# APM32F103x4 register map
File version: 1.0
CPU: CM3 r2p1, little endian, no MPU, no FPU, 4 interrupt priority bits
Registers are 32-bit, read-write, reset 0x0 unless marked. A register's access mark holds for its fields unless they carry their own. Offsets are from the block's base; [hi:lo] are bit positions; {n}, {i} and the like mark numbered series.

## GPIOA — General purpose I/O
Base 0x40010800
Same registers: GPIOB 0x40010C00, GPIOC 0x40011000, GPIOD 0x40011400
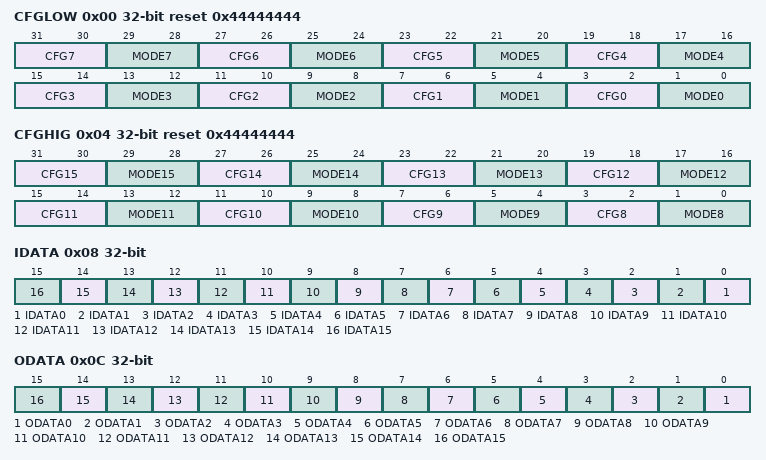
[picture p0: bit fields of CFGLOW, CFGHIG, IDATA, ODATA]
0x00 CFGLOW reset 0x44444444 — Port configuration register 0 (GPIOn_CFGLOW)
  [31:30] CFG7 — Port n.7 configuration bits
  [29:28] MODE7 — Port n.7 mode bits
  [27:26] CFG6 — Port n.6 configuration bits
  [25:24] MODE6 — Port n.6 mode bits
  [23:22] CFG5 — Port n.5 configuration bits
  [21:20] MODE5 — Port n.5 mode bits
  [19:18] CFG4 — Port n.4 configuration bits
  [17:16] MODE4 — Port n.4 mode bits
  [15:14] CFG3 — Port n.3 configuration bits
  [13:12] MODE3 — Port n.3 mode bits
  [11:10] CFG2 — Port n.2 configuration bits
  [9:8] MODE2 — Port n.2 mode bits
  [7:6] CFG1 — Port n.1 configuration bits
  [5:4] MODE1 — Port n.1 mode bits
  [3:2] CFG0 — Port n.0 configuration bits
  [1:0] MODE0 — Port n.0 mode bits
0x04 CFGHIG reset 0x44444444 — Port configuration register 1 (GPIOn_CFGHIG)
  [31:30] CFG15 — Port n.15 configuration bits
  [29:28] MODE15 — Port n.15 mode bits
  [27:26] CFG14 — Port n.14 configuration bits
  [25:24] MODE14 — Port n.14 mode bits
  [23:22] CFG13 — Port n.13 configuration bits
  [21:20] MODE13 — Port n.13 mode bits
  [19:18] CFG12 — Port n.12 configuration bits
  [17:16] MODE12 — Port n.12 mode bits
  [15:14] CFG11 — Port n.11 configuration bits
  [13:12] MODE11 — Port n.11 mode bits
  [11:10] CFG10 — Port n.10 configuration bits
  [9:8] MODE10 — Port n.10 mode bits
  [7:6] CFG9 — Port n.9 configuration bits
  [5:4] MODE9 — Port n.9 mode bits
  [3:2] CFG8 — Port n.8 configuration bits
  [1:0] MODE8 — Port n.8 mode bits
0x08 IDATA ro — Port input data register (GPIOn_IDATA)
  [n] IDATA{n} (n=0..15) — Port input data
0x0C ODATA — Port output data register (GPIOn_ODATA)
  [n] ODATA{n} (n=0..15) — Port output data
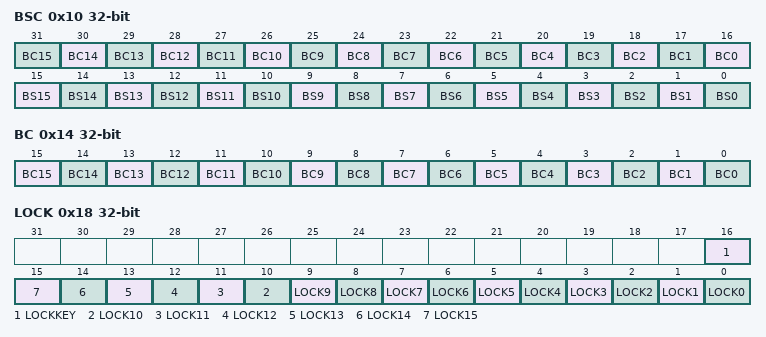
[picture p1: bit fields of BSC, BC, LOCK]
0x10 BSC wo — Port bit set/reset register (GPIOn_BSC)
  [n+16] BC{n} (n=0..15) — Clear bit {n}
  [n] BS{n} (n=3..15) — Set bit {n}
  [2] BS2 — Set bit 1
  [1] BS1 — Set bit 1
  [0] BS0 — Set bit 0
0x14 BC wo — Port bit clear register (GPIOn_BC)
  [n] BC{n} (n=3..15) — Clear bit {n}
  [2] BC2 — Clear bit 1
  [1] BC1 — Clear bit 1
  [0] BC0 — Clear bit 0
0x18 LOCK — Port configuration lock register (GPIOn_LOCK)
  [16] LOCKKEY
  [n] LOCK{n} (n=0..15) — Port A Lock bit {n}

## EINT — External Interrupt
Base 0x40010400
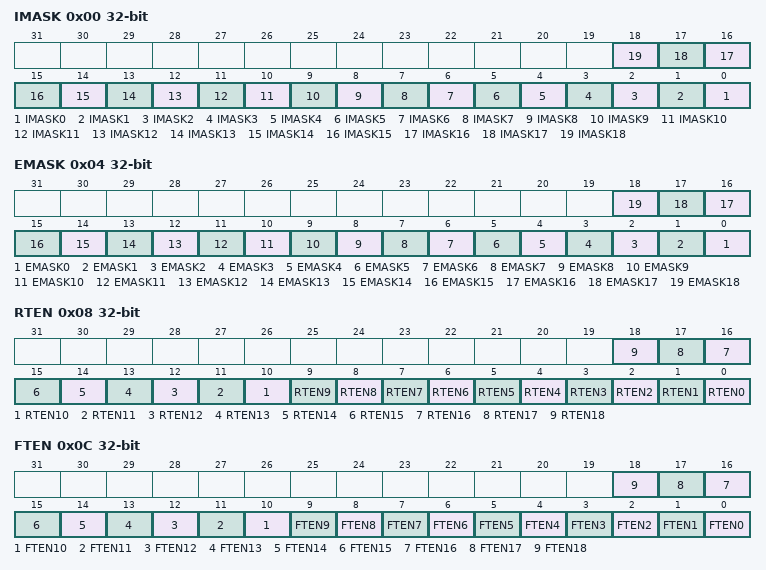
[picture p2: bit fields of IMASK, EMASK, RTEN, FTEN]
0x00 IMASK — Interrupt mask register (EINT_IMASK)
  [n] IMASK{n} (n=0..18) — Interrupt Mask on line {n}
0x04 EMASK — Event mask register (EINT_EMASK)
  [n] EMASK{n} (n=0..18) — Event Mask on line {n}
0x08 RTEN — Rising Trigger selection register (EINT_RTEN)
  [n] RTEN{n} (n=0..18) — Rising trigger event configuration of line {n}
0x0C FTEN — Falling Trigger selection register (EINT_FTEN)
  [n] FTEN{n} (n=0..18) — Falling trigger event configuration of line {n}
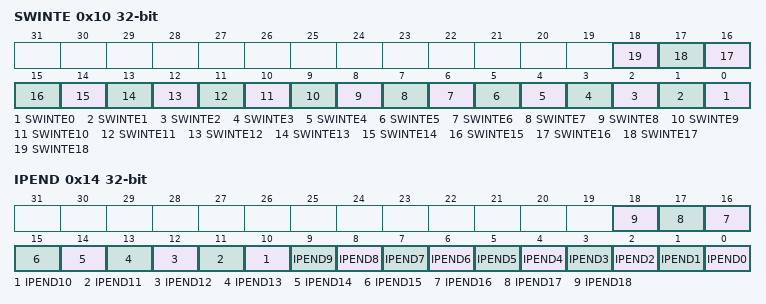
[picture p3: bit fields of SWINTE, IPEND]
0x10 SWINTE — Software interrupt event register (EINT_SWINTE)
  [n] SWINTE{n} (n=0..18) — Software Interrupt on line {n}
0x14 IPEND — Interrupt Flag Enable register (EINT_IPEND)
  [n] IPEND{n} (n=0..18) — Pending bit {n}

## AFIO — Alternate function I/O
Base 0x40010000
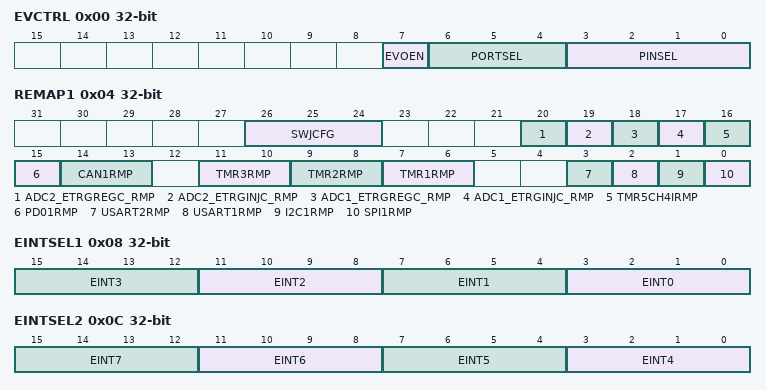
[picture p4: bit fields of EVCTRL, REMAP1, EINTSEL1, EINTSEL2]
0x00 EVCTRL — Event control register (AFIO_EVCTRL)
  [7] EVOEN, [6:4] PORTSEL, [3:0] PINSEL
0x04 REMAP1 access per field — Alternate function IO remap and Serial wire JTAG configuration register (AFIO_REMAP1)
  [26:24] SWJCFG wo — Serial wire JTAG configuration
  [20] ADC2_ETRGREGC_RMP rw — ADC 2 external trigger regular conversion remapping
  [19] ADC2_ETRGINJC_RMP rw — ADC 2 external trigger injected conversion remapping
  [18] ADC1_ETRGREGC_RMP rw — ADC 1 external trigger regular conversion remapping
  [17] ADC1_ETRGINJC_RMP rw — ADC 1 External trigger injected conversion remapping
  [16] TMR5CH4IRMP rw — TMR5 channel4 internal remap
  [15] PD01RMP rw — Port D0/Port D1 mapping on OSC_IN/OSC_OUT
  [14:13] CAN1RMP rw — CAN1 alternate function remapping
  [11:10] TMR3RMP rw — TMR3 remapping
  [9:8] TMR2RMP rw — TMR2 remapping
  [7:6] TMR1RMP rw — TMR1 remapping
  [3] USART2RMP rw — USART2 remapping
  [2] USART1RMP rw — USART1 remapping
  [1] I2C1RMP rw — I2C1 remapping
  [0] SPI1RMP rw — SPI1 remapping
0x08 EINTSEL1 — External interrupt configuration register1 (AFIO_EINTSEL1)
  [4n+3:4n] EINT{n} (n=0..3) — EINT {n} configuration
0x0C EINTSEL2 — External interrupt configuration register2 (AFIO_EINTSEL2)
  [4n-13:4n-16] EINT{n} (n=4..7) — EINT {n} configuration
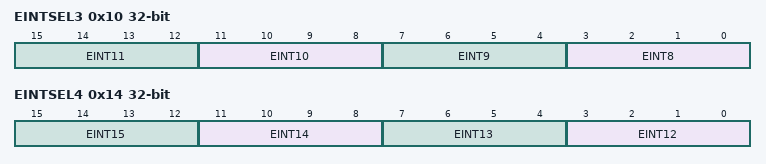
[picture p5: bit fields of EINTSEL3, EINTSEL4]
0x10 EINTSEL3 — External interrupt configuration register3 (AFIO_EINTSEL3)
  [4n-29:4n-32] EINT{n} (n=8..11) — EINT {n} configuration
0x14 EINTSEL4 — External interrupt configuration register4 (AFIO_EINTSEL4)
  [4n-45:4n-48] EINT{n} (n=12..15) — EINT {n} configuration
